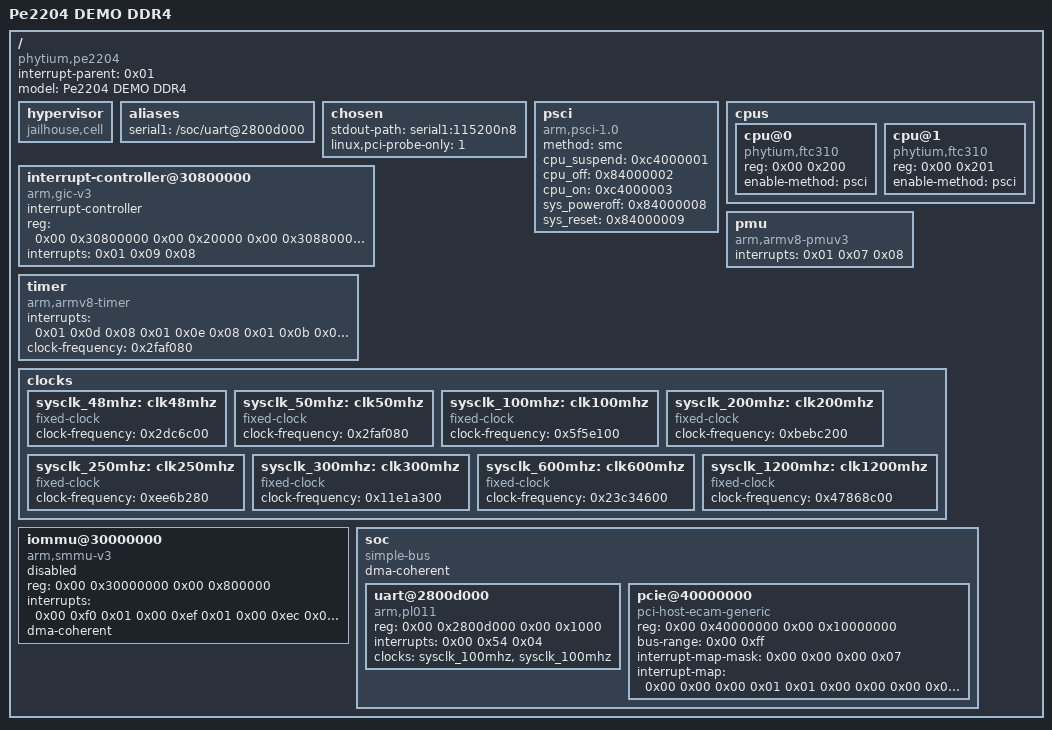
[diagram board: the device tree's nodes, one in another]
/*
 * Configuration for phytium e2000q chip linux demo,
 * corresponding to configs/arm64/phytium-e2000q-linux-demo.c.
 *
 * Copyright (C) 2023, Phytium Technology Co., Ltd.
 *
 * Authors:
 *  yangshaojun <yangshaojun@phytium.com.cn>
 *
 * This work is licensed under the terms of the GNU GPL, version 2.  See
 * the COPYING file in the top-level directory.
 */

/dts-v1/;

/memreserve/	0x0000000080000000 0x0000000000010000;
/ {
	compatible = "phytium,pe2204";
	interrupt-parent = <0x01>;
	#address-cells = <0x02>;
	#size-cells = <0x02>;
	model = "Pe2204 DEMO DDR4";

	hypervisor {
		compatible = "jailhouse,cell";
	};

	aliases {
		serial1 = "/soc/uart@2800d000";
	};

	chosen {
		stdout-path = "serial1:115200n8";
		linux,pci-probe-only = <1>;
	};

	psci {
		compatible = "arm,psci-1.0";
		method = "smc";
		cpu_suspend = <0xc4000001>;
		cpu_off = <0x84000002>;
		cpu_on = <0xc4000003>;
		sys_poweroff = <0x84000008>;
		sys_reset = <0x84000009>;
	};

	cpus {
		#address-cells = <0x02>;
		#size-cells = <0x00>;

		cpu@0 {
			device_type = "cpu";
			compatible = "phytium,ftc310\0arm,armv8";
			reg = <0x00 0x200>;
			enable-method = "psci";
		};

		cpu@1 {
			device_type = "cpu";
			compatible = "phytium,ftc310\0arm,armv8";
			reg = <0x00 0x201>;
			enable-method = "psci";
		};
	};

	interrupt-controller@30800000 {
		compatible = "arm,gic-v3";
		#interrupt-cells = <0x03>;
		#address-cells = <0x02>;
		#size-cells = <0x02>;
		ranges;
		interrupt-controller;
		reg = <0x00 0x30800000 0x00 0x20000 0x00 0x30880000 0x00 0x80000 0x00 0x30840000 0x00 0x10000 0x00 0x30850000 0x00 0x10000 0x00 0x30860000 0x00 0x10000>;
		interrupts = <0x01 0x09 0x08>;
		phandle = <0x01>;
	};

	pmu {
		compatible = "arm,armv8-pmuv3";
		interrupts = <0x01 0x07 0x08>;
	};

	timer {
		compatible = "arm,armv8-timer";
		interrupts = <0x01 0x0d 0x08 0x01 0x0e 0x08 0x01 0x0b 0x08 0x01 0x0a 0x08>;
		clock-frequency = <0x2faf080>;
	};

	clocks {
		#address-cells = <0x02>;
		#size-cells = <0x02>;
		ranges;

		sysclk_48mhz: clk48mhz {
			compatible = "fixed-clock";
			#clock-cells = <0x00>;
			clock-frequency = <0x2dc6c00>;
			phandle = <0x13>;
		};

		sysclk_50mhz: clk50mhz {
			compatible = "fixed-clock";
			#clock-cells = <0x00>;
			clock-frequency = <0x2faf080>;
			phandle = <0x0c>;
		};

		sysclk_100mhz: clk100mhz {
			compatible = "fixed-clock";
			#clock-cells = <0x00>;
			clock-frequency = <0x5f5e100>;
			phandle = <0x0d>;
		};

		sysclk_200mhz: clk200mhz {
			compatible = "fixed-clock";
			#clock-cells = <0x00>;
			clock-frequency = <0xbebc200>;
			phandle = <0x11>;
		};

		sysclk_250mhz: clk250mhz {
			compatible = "fixed-clock";
			#clock-cells = <0x00>;
			clock-frequency = <0xee6b280>;
			phandle = <0x12>;
		};

		sysclk_300mhz: clk300mhz {
			compatible = "fixed-clock";
			#clock-cells = <0x00>;
			clock-frequency = <0x11e1a300>;
		};

		sysclk_600mhz: clk600mhz {
			compatible = "fixed-clock";
			#clock-cells = <0x00>;
			clock-frequency = <0x23c34600>;
			phandle = <0x0e>;
		};

		sysclk_1200mhz: clk1200mhz {
			compatible = "fixed-clock";
			#clock-cells = <0x00>;
			clock-frequency = <0x47868c00>;
			phandle = <0x0b>;
		};
	};

	iommu@30000000 {
		compatible = "arm,smmu-v3";
		reg = <0x00 0x30000000 0x00 0x800000>;
		interrupts = <0x00 0xf0 0x01 0x00 0xef 0x01 0x00 0xec 0x01 0x00 0xf2 0x01>;
		interrupt-names = "eventq\0priq\0cmdq-sync\0gerror";
		dma-coherent;
		#iommu-cells = <0x01>;
		status = "disabled";
	};

	soc {
		compatible = "simple-bus";
		#address-cells = <0x02>;
		#size-cells = <0x02>;
		dma-coherent;
		ranges;

		uart@2800d000 {
			compatible = "arm,pl011\0arm,primecell";
			reg = <0x00 0x2800d000 0x00 0x1000>;
			interrupts = <0x00 0x54 0x04>;
			clocks = <&sysclk_100mhz &sysclk_100mhz>;
			clock-names = "uartclk\0apb_pclk";
			status = "okay";
		};

		pcie@40000000 {
			compatible = "pci-host-ecam-generic";
			device_type = "pci";
			#address-cells = <0x03>;
			#size-cells = <0x02>;
			#interrupt-cells = <0x01>;
			reg = <0x00 0x40000000 0x00 0x10000000>;
			bus-range = <0x00 0xff>;
			interrupt-map-mask = <0x00 0x00 0x00 0x07>;
			interrupt-map = <0x00 0x00 0x00 0x01 0x01 0x00 0x00 0x00 0x04 0x04
			                 0x00 0x00 0x00 0x02 0x01 0x00 0x00 0x00 0x05 0x04
			                 0x00 0x00 0x00 0x03 0x01 0x00 0x00 0x00 0x06 0x04
			                 0x00 0x00 0x00 0x04 0x01 0x00 0x00 0x00 0x07 0x04>;
			ranges = <0x1000000 0x00 0x00 0x00 0x50000000 0x00 0xf00000 0x2000000 0x00 0x58000000 0x00 0x58000000 0x00 0x28000000 0x3000000 0x10 0x00 0x10 0x00 0x10 0x00>;
			status = "okay";
		};
	};
};

